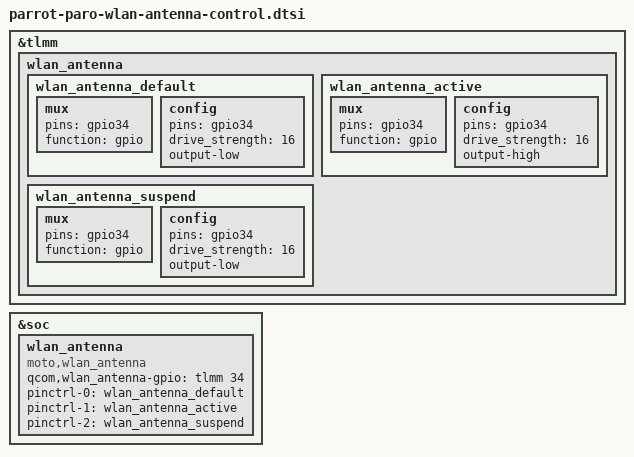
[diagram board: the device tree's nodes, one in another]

&tlmm {
	wlan_antenna {
        wlan_antenna_default: wlan_antenna_default {
            mux {
                    pins = "gpio34";
                    function = "gpio";
            };
            config {
                    pins = "gpio34";
                    drive_strength = <16>;
                    output-low;
            };
        };

        wlan_antenna_active: wlan_antenna_active {
            mux {
                    pins = "gpio34";
                    function = "gpio";
            };
            config {
                    pins = "gpio34";
                    drive_strength = <16>;
                    output-high;
            };
        };

        wlan_antenna_suspend: wlan_antenna_suspend {
            mux {
                    pins = "gpio34";
                    function = "gpio";
            };
            config {
                    pins = "gpio34";
                    drive_strength = <16>;
                    output-low;
            };
        };
	};
};

&soc {
	wlan_antenna: wlan_antenna {
		status = "ok";
		compatible = "moto,wlan_antenna";
		qcom,wlan_antenna-gpio = <&tlmm 34 0>;
		pinctrl-names = "default", "antenna_active", "antenna_suspend";
		pinctrl-0 = <&wlan_antenna_default>;
		pinctrl-1 = <&wlan_antenna_active>;
		pinctrl-2 = <&wlan_antenna_suspend>;
	};
};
